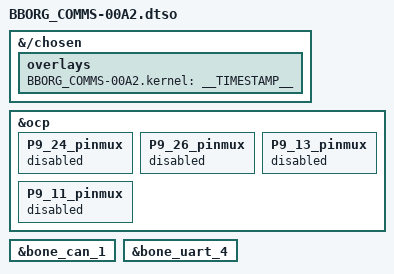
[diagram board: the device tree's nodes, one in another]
// SPDX-License-Identifier: GPL-2.0-only
/*
 * Copyright (C) 2012,2019 Texas Instruments Incorporated - https://www.ti.com/
 * Copyright (C) 2015 Robert Nelson <robertcnelson@gmail.com>
 * Copyright (C) 2015 Sebastian Jegerås
 */

/*
 *
 * sudo ip link set can0 type can bitrate 500000
 * sudo ifconfig can0 up
 *
 * candump can0
 * cansend can0 123#DEADBEEF
 */

/dts-v1/;
/plugin/;

#include <dt-bindings/gpio/gpio.h>

/*
 * Helper to show loaded overlays under: /proc/device-tree/chosen/overlays/
 */
&{/chosen} {
	overlays {
		BBORG_COMMS-00A2.kernel = __TIMESTAMP__;
	};
};

/*
 * Free up the pins used by the cape from the pinmux helpers.
 */
&ocp {
	P9_24_pinmux { status = "disabled"; };
	P9_26_pinmux { status = "disabled"; };
	P9_13_pinmux { status = "disabled"; };
	P9_11_pinmux { status = "disabled"; };
};

&bone_can_1 {
	status = "okay";
};

&bone_uart_4 {
	status = "okay";
};
